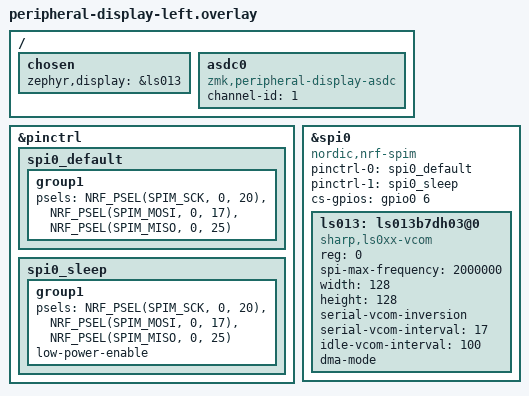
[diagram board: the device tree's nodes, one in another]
/*
 * Sharp LS013B7DH03 display on the peripheral (left) half.
 *
 * SPI0: SCK = P0.20, MOSI = P0.17, MISO = P0.25, CS = P0.06 (active high).
 */
#include <zephyr/dt-bindings/gpio/gpio.h>

/ {
    chosen {
        zephyr,display = &ls013;
    };

    asdc0: asdc0 {
        compatible = "zmk,peripheral-display-asdc";
        channel-id = <1>;
        status = "okay";
    };
};

&pinctrl {
    spi0_default: spi0_default {
        group1 {
            psels = <NRF_PSEL(SPIM_SCK, 0, 20)>,
                <NRF_PSEL(SPIM_MOSI, 0, 17)>,
                <NRF_PSEL(SPIM_MISO, 0, 25)>;
        };
    };

    spi0_sleep: spi0_sleep {
        group1 {
            psels = <NRF_PSEL(SPIM_SCK, 0, 20)>,
                <NRF_PSEL(SPIM_MOSI, 0, 17)>,
                <NRF_PSEL(SPIM_MISO, 0, 25)>;
            low-power-enable;
        };
    };
};

nice_view_spi: &spi0 {
    status = "okay";
    compatible = "nordic,nrf-spim";
    pinctrl-0 = <&spi0_default>;
    pinctrl-1 = <&spi0_sleep>;
    pinctrl-names = "default", "sleep";
    cs-gpios = <&gpio0 6 GPIO_ACTIVE_HIGH>;
    ls013: ls013b7dh03@0 {
        compatible = "sharp,ls0xx-vcom";
        reg = <0>;
        spi-max-frequency = <2000000>;
        width = <128>;
        height = <128>;
        serial-vcom-inversion;
        serial-vcom-interval = <17>;
        idle-vcom-interval = <100>;
        dma-mode;
    };
};
